# STM32H553xx register map
File version: 1.0
Registers are 32-bit, read-write, reset 0x0 unless marked. A register's access mark holds for its fields unless they carry their own. Offsets are from the block's base; [hi:lo] are bit positions; {n}, {i} and the like mark numbered series.

## PLAY1 — Programmable Logic Array (PLAY)
Base 0x44008000
Same registers: PLAY1_S 0x54008000
0x00 CFGCR — PLAY Configuration Control Register
  [0] UNLOCK — Unlock configuration
0x04 SECCFGR — PLAY Security attributes Configuration Register
  [1:0] SEC — Security configuration
    1=SEC_ITEM_CONFIG (PLAY configuration registers items); 3=SEC_ITEM_ALL (All PLAY registers items); 0=ATTR_NSEC (Non-secure attribute)
0x08 PRIVCFGR — PLAY Privilege attributes Configuration Register
  [1:0] PRIV — Privilege configuration
    1=PRIV_ITEM_CONFIG (PLAY configuration registers items); 3=PRIV_ITEM_ALL (All PLAY registers items); 0=ATTR_NPRIV (Non-privileged attribute)
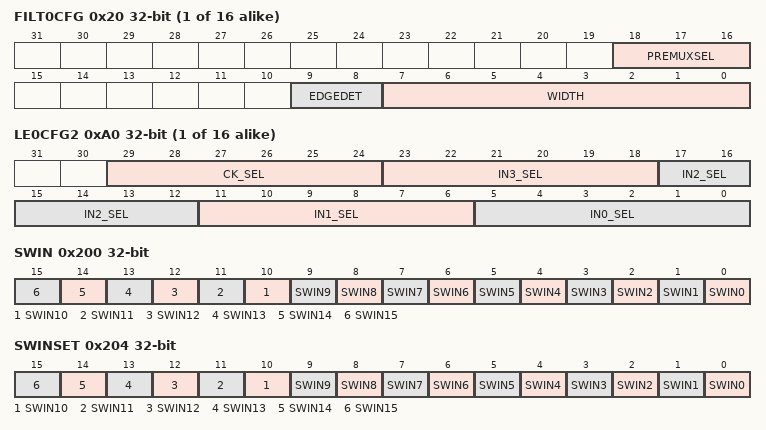
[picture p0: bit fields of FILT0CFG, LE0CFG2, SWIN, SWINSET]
{0x20+4i} FILT{i}CFG (i=0..15) — PLAY Filter Configuration Registers
  [18:16] PREMUXSEL — Input Pre-Multiplexer Selection
  [9:8] EDGEDET — Edge Detection mode
  [7:0] WIDTH — Minimum Pulse Width
    {v}=IN{v} (Input {v}) (v=0..15)
{0x60+4i} LE{i}CFG1 (i=0..15) — PLAY Logic Element Configuration Registers 1
  [15:0] LUT — Look-Up Table contents
    {v}=Lookup table {v} (v=0..15)
{0xA0+4i} LE{i}CFG2 (i=0..15) — PLAY Logic Element Configuration Registers 2
  [29:24] CK_SEL — Clock Enable Selection
  [6n+5:6n] IN{n}_SEL (n=0..3) — Logic Element Input {n}
{0x100+4i} OUT{i}CFG (i=0..15) — PLAY Output Configuration Registers
  [4:0] SEL — Output source Selection
0x200 SWIN — PLAY Software Input Status Register
  [n] SWIN{n} (n=0..15) — Input SWIN{n} state
0x204 SWINSET — PLAY Software Input Set Register
  [n] SWIN{n} (n=0..15) — Set SWIN{n} input
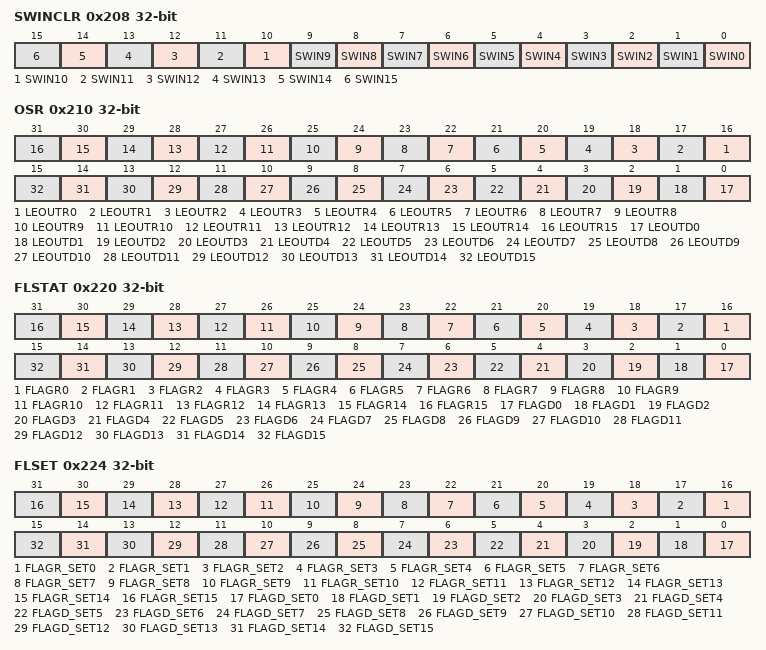
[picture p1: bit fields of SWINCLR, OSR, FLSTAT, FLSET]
0x208 SWINCLR — PLAY Software Input Clear Register
  [n] SWIN{n} (n=0..15) — Reset SWIN{n} input
0x210 OSR — PLAY Output Status Register
  [n+16] LEOUTR{n} (n=0..15) — LEOUTR{n} output
  [n] LEOUTD{n} (n=0..15) — LEOUTD{n} output
0x220 FLSTAT — PLAY Flag Status Register
  [n+16] FLAGR{n} (n=0..15) — Flag Output Register {n}
  [n] FLAGD{n} (n=0..15) — Flag Output Direct{n}
0x224 FLSET — PLAY Flag Set Register
  [n+16] FLAGR_SET{n} (n=0..15) — Flag Output Register {n}
  [n] FLAGD_SET{n} (n=0..15) — Flag Output Direct{n}
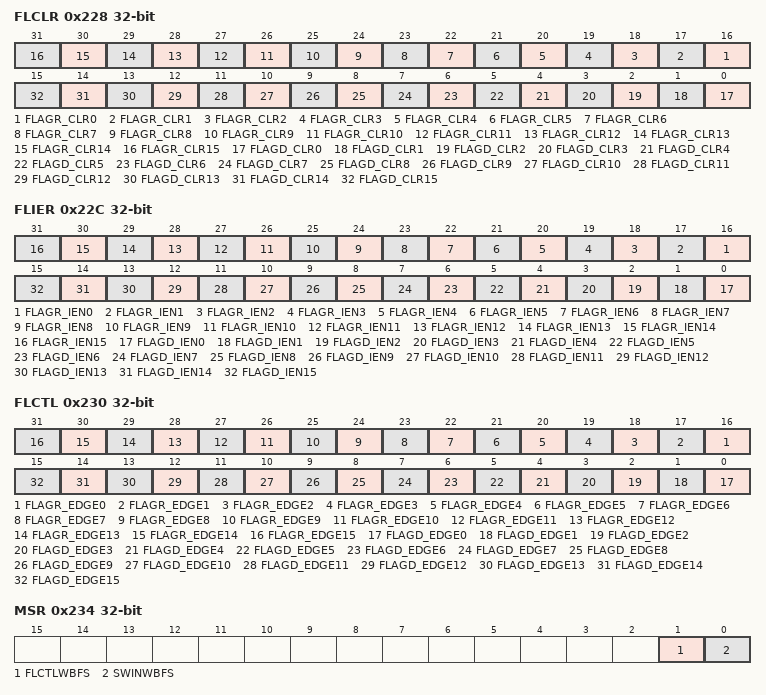
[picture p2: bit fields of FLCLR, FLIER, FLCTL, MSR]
0x228 FLCLR — PLAY Flag Clear Register
  [n+16] FLAGR_CLR{n} (n=0..15) — Flag Output Register {n}
  [n] FLAGD_CLR{n} (n=0..15) — Flag Output Direct{n}
0x22C FLIER — PLAY Flag Interrupt Enable Register
  [n+16] FLAGR_IEN{n} (n=0..15) — Flag Interrupt Output Register {n}
  [n] FLAGD_IEN{n} (n=0..15) — Flag Interrupt Output Direct{n}
0x230 FLCTL — PLAY Flag Control Register
  [n+16] FLAGR_EDGE{n} (n=0..15) — Edge Direction for Output Register {n}
  [n] FLAGD_EDGE{n} (n=0..15) — Edge Direction for Output Direct{n}
0x234 MSR — PLAY Miscellaneous Status Register
  [1] FLCTLWBFS — FLCTL Register Write Busy Flag Status
  [0] SWINWBFS — SWIN Register Write Busy Flag Status
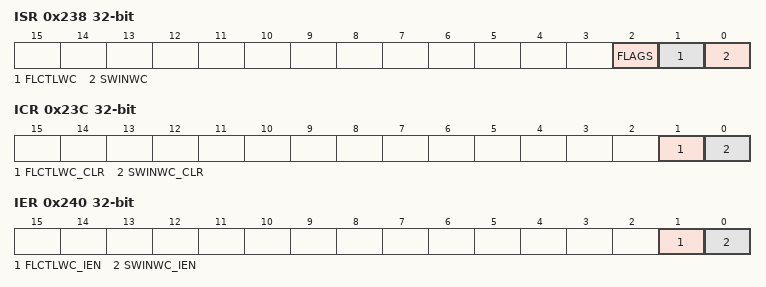
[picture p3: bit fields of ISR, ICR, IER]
0x238 ISR — PLAY Interrupt Status Register
  [2] FLAGS — Flags Interrupt Status
  [1] FLCTLWC — FLCTL Register Write Complete Interrupt Status
  [0] SWINWC — SWIN Register Write Complete Interrupt Status
0x23C ICR — PLAY Interrupt Clear Register
  [1] FLCTLWC_CLR — FLCTL Register Write Complete Clear Interrupt
  [0] SWINWC_CLR — SWIN Register Write Complete Clear Interrupt
0x240 IER — PLAY Interrupt Enable Register
  [1] FLCTLWC_IEN — FLCTL Register Write Complete Interrupt Enable
  [0] SWINWC_IEN — SWIN Register Write Complete Interrupt Enable

## PWR — Power Control
Base 0x44020800
Same registers: PWR_S 0x54020800
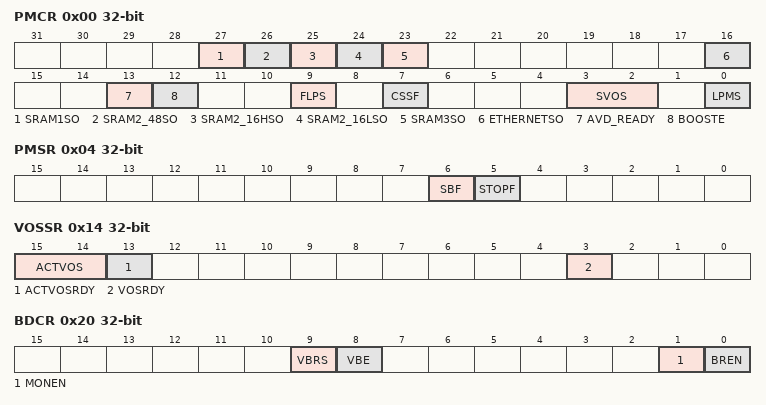
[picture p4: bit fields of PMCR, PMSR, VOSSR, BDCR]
0x00 PMCR — Power mode control register
  [27] SRAM1SO
  [26] SRAM2_48SO
  [25] SRAM2_16HSO
  [24] SRAM2_16LSO
  [23] SRAM3SO
  [16] ETHERNETSO
  [13] AVD_READY
  [12] BOOSTE
  [9] FLPS
  [7] CSSF
  [3:2] SVOS
    3=SCALE3 (Select voltage scale 3 when system enters STOP mode); 2=SCALE4 (Select voltage scale 4 when system enters STOP mode); 1=SCALE5 (Select voltage scale 5 when system enters STOP mode)
  [0] LPMS
    0=STOP_MODE (STOP 0 mode); 1=STANDBY_MODE
0x04 PMSR — Power mode status register
  [6] SBF, [5] STOPF
0x10 VOSCR — Voltage scaling control register
  [5:4] VOS
    3=SCALE0 (Voltage scaling range 0); 2=SCALE1 (Voltage scaling range 1); 1=SCALE2 (Voltage scaling range 2); 0=SCALE3 (Voltage scaling range 3)
0x14 VOSSR — Voltage sacling status register
  [15:14] ACTVOS, [13] ACTVOSRDY, [3] VOSRDY
0x20 BDCR — BacKup domain control register
  [9] VBRS
    0=RESISTOR_5K (Charge the battery through a 5 kO resistor); 1=RESISTOR_1_5K (Charge the battery through a 1.5 kO resistor)
  [8] VBE
  [1] MONEN
  [0] BREN
0x24 DBPCR — DBP control register
  [0] DBP
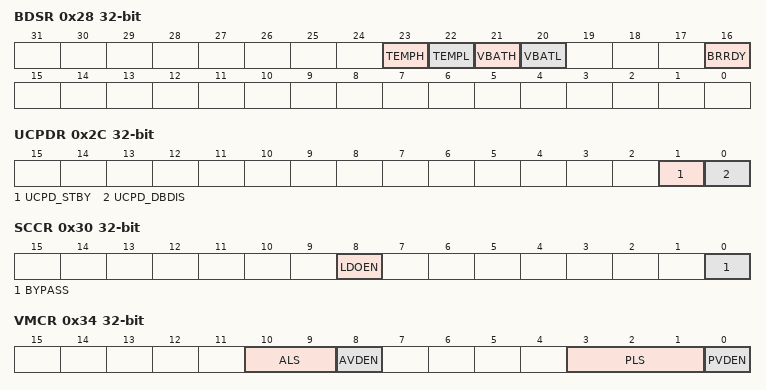
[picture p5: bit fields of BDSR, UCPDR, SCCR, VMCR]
0x28 BDSR — BacKup domain status register
  [23] TEMPH, [22] TEMPL, [21] VBATH, [20] VBATL, [16] BRRDY
0x2C UCPDR — Usb typeC and Power Delivery Register
  [1] UCPD_STBY, [0] UCPD_DBDIS
0x30 SCCR — Supply configuration control register
  [8] LDOEN, [0] BYPASS
0x34 VMCR — Voltage Monitor Control Register
  [10:9] ALS
    0=AVDLEVEL_0 (Analog Voltage threshold detected by AVD 1.7 V); 1=AVDLEVEL_1 (Analog Voltage threshold detected by AVD 2.1 V); 2=AVDLEVEL_2 (Analog Voltage threshold detected by AVD 2.5 V); 3=AVDLEVEL_3 (Analog Voltage threshold detected by AVD 2.8 V)
  [8] AVDEN
  [3:1] PLS
    0=PVDLEVEL_0 (Voltage threshold detected by PVD 1.95 V); 1=PVDLEVEL_1 (Voltage threshold detected by PVD 2.10 V); 2=PVDLEVEL_2 (Voltage threshold detected by PVD 2.25 V); 3=PVDLEVEL_3 (Voltage threshold detected by PVD 2.40 V); 4=PVDLEVEL_4 (Voltage threshold detected by PVD 2.55 V); 5=PVDLEVEL_5 (Voltage threshold detected by PVD 2.70 V); 6=PVDLEVEL_6 (Voltage threshold detected by PVD 2.85 V); 7=PVDLEVEL_7
  [0] PVDEN
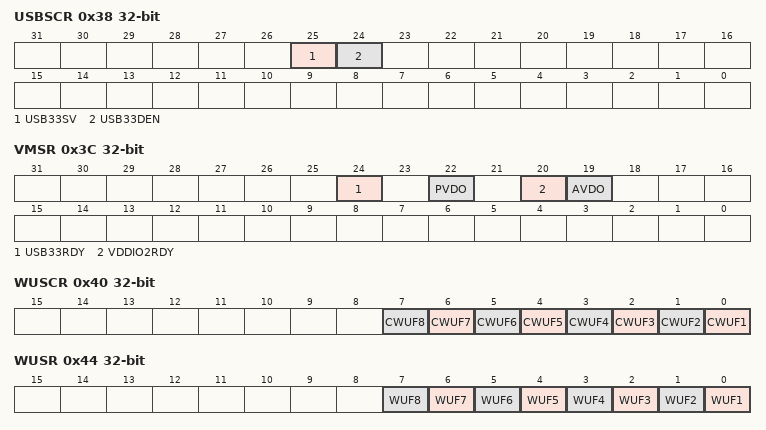
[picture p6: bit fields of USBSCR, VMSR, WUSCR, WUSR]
0x38 USBSCR — USB Supply Control Register
  [25] USB33SV, [24] USB33DEN
0x3C VMSR — Status Register Voltage Monitoring
  [24] USB33RDY, [22] PVDO, [20] VDDIO2RDY, [19] AVDO
0x40 WUSCR — WakeUP status clear register
  [n-1] CWUF{n} (n=1..8)
0x44 WUSR — WakeUP status Register
  [n-1] WUF{n} (n=1..8)
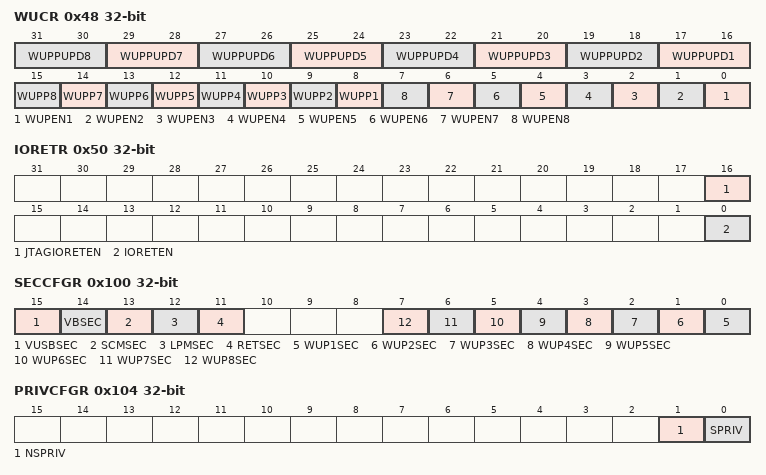
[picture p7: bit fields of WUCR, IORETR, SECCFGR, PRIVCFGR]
0x48 WUCR — WakeUP configuration register
  [2n+15:2n+14] WUPPUPD{n} (n=1..8), [n+7] WUPP{n} (n=1..8), [n-1] WUPEN{n} (n=1..8)
0x50 IORETR — IO RETention Register
  [16] JTAGIORETEN, [0] IORETEN
0x100 SECCFGR — Security configuration register
  [15] VUSBSEC, [14] VBSEC, [13] SCMSEC, [12] LPMSEC, [11] RETSEC, [n-1] WUP{n}SEC (n=1..8)
0x104 PRIVCFGR — Privilege configuration register
  [1] NSPRIV, [0] SPRIV
